AUTOSAR XML (schema 4-2-1)
package /VehicleProject
  system System
package /NM
  nm config NmConfig: can-nm-cluster-coupling=coupled-cluster=CAN00_CAN
    can nm cluster CAN00_CAN: communication-cluster=CAN00, nm-channel-id=0, nm-msg-cycle-time=0.1, nm-network-timeout=1, nm-repeat-message-time=0.4, nm-user-data-length=6, nm-wait-bus-sleep-time=0.75
      can nm node MyECU: controller=CT_CAN00, nm-if-ecu=MyECU_CAN, nm-node-id=0, rx-nm-pdu=msg_nm_RearECU_oCAN00, tx-nm-pdu=msg_nm_MyECU_oCAN00, nm-msg-cycle-offset=0, nm-msg-reduced-time=0.05, nm-range-config={lower-can-id=1024, upper-can-id=1087}
      can nm node RearECU: nm-if-ecu=RearECU_CAN, nm-node-id=1, rx-nm-pdu=msg_nm_MyECU_oCAN00, tx-nm-pdu=msg_nm_RearECU_oCAN00, nm-msg-cycle-offset=0, nm-msg-reduced-time=0.05, nm-range-config={lower-can-id=1024, upper-can-id=1087}
      can nm node Tester: nm-if-ecu=Tester_CAN, nm-node-id=0, nm-passive-mode-enabled=true, nm-msg-cycle-offset=0, nm-msg-reduced-time=0.05, nm-range-config={lower-can-id=1024, upper-can-id=1087}
    nm-if-ecus:
      nm ecu MyECU_CAN: ecu-instance=MyECU, nm-node-id-enabled=true, nm-user-data-enabled=true
      nm ecu RearECU_CAN: nm-node-id-enabled=true, nm-user-data-enabled=true
      nm ecu Tester_CAN: nm-node-id-enabled=true, nm-passive-mode-enabled=true, nm-user-data-enabled=true
package /TP
  can tp config CAN00_CAN: communication-cluster=CAN00, can-tp-ecu{cycle-time-main-function=0.005, ecu-instance=MyECU}
    can tp channel TPCH: channel-id=0, channel-mode=FULL-DUPLEX-MODE
    can-tp-connection addressing-format=STANDARD, can-tp-channel=TPCH, data-pdu=msg_diag_RequestGlobal_Tp_oCAN00, receiver=TN_MyECU, ta-type=FUNCTIONAL, tp-sdu=msg_diag_RequestGlobal_oCAN00, transmitter=TN_Tester:
      ident msg_diag_RequestGlobal_oTN_Tester
    can-tp-connection addressing-format=STANDARD, can-tp-channel=TPCH, data-pdu=msg_diag_Request_MyECU_Tp_oCAN00, flow-control-pdu=msg_diag_Response_MyECU_Tp_oCAN00, receiver=TN_MyECU, ta-type=PHYSICAL, tp-sdu=msg_diag_Request_MyECU_oCAN00, transmitter=TN_Tester:
      ident msg_diag_Request_MyECU_oTN_MyECU
    can-tp-connection addressing-format=STANDARD, can-tp-channel=TPCH, data-pdu=msg_diag_Response_MyECU_Tp_oCAN00, flow-control-pdu=msg_diag_Request_MyECU_Tp_oCAN00, receiver=TN_Tester, ta-type=PHYSICAL, tp-sdu=msg_diag_Response_MyECU_oCAN00, transmitter=TN_MyECU:
      ident msg_diag_Response_MyECU_oTN_MyECU
    can tp node TN_MyECU: connector=CN_CAN00
    can tp node TN_Tester
package /Cluster
  can cluster CAN00: protocol-name=CAN
    can physical channel CHNL: comm-connectors=CN_CAN00
      frame msg_diag_Request_MyECU_oCAN00: id 0x610, to MyECU, frame-length=8, can-addressing-mode=STANDARD
        n pdu msg_diag_Request_MyECU_Tp_oCAN00: length=8
      frame msg_diag_RequestGlobal_oCAN00: id 0x614, to MyECU, frame-length=8, can-addressing-mode=STANDARD
        n pdu msg_diag_RequestGlobal_Tp_oCAN00: length=8
      frame msg_diag_Response_MyECU_oCAN00: id 0x612, from MyECU, frame-length=8, can-addressing-mode=STANDARD
        n pdu msg_diag_Response_MyECU_Tp_oCAN00: length=8
      frame msg_MyECU_Lamp_oCAN00: id 0x511, from MyECU, frame-length=8, can-addressing-mode=STANDARD
        pdu msg_MyECU_Lamp_oCAN00: length=8, minimum-delay=0, transmission-mode-false-timing=cyclic-timing={time-offset=0, time-period=0.1}, transmission-mode-true-timing=cyclic-timing={time-offset=0, time-period=0.1}, unused-bit-pattern=0
          signal sig_LampCnt_omsg_MyECU_Lamp_oCAN00: start 7, 8 bit, big-endian, init-value=0, base-type=uint8, data-constr=DC_sig_LampCnt, transfer-property=PENDING
      frame msg_nm_MyECU_oCAN00: id 0x400, from MyECU, frame-length=8, can-addressing-mode=STANDARD
        nm pdu msg_nm_MyECU_oCAN00: length=8, unused-bit-pattern=0
      frame msg_nm_RearECU_oCAN00: id 0x401, to MyECU, frame-length=8, can-addressing-mode=STANDARD
        nm pdu msg_nm_RearECU_oCAN00: length=8, unused-bit-pattern=0
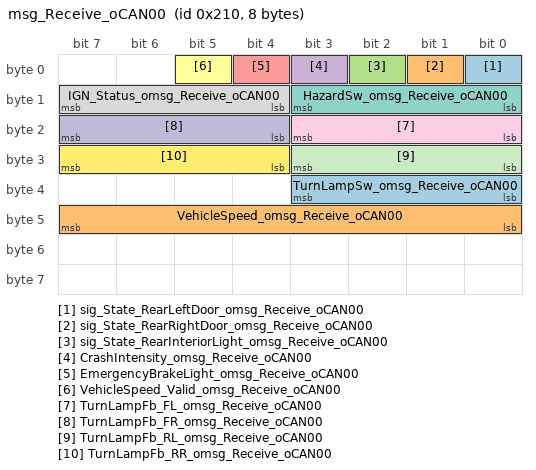
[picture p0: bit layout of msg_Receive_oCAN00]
      frame msg_Receive_oCAN00: id 0x210, to MyECU, frame-length=8, can-addressing-mode=STANDARD
        pdu msg_Receive_oCAN00: length=8, minimum-delay=0, transmission-mode-false-timing=cyclic-timing={time-offset=0, time-period=0.1}, transmission-mode-true-timing=cyclic-timing={time-offset=0, time-period=0.1}, unused-bit-pattern=0
          signal sig_State_RearLeftDoor_omsg_Receive_oCAN00: start 0, 1 bit, little-endian, init-value=0, base-type=boolean, data-constr=DC_sig_State_RearLeftDoor, transfer-property=PENDING, to MyECU
          signal sig_State_RearRightDoor_omsg_Receive_oCAN00: start 1, 1 bit, little-endian, init-value=0, base-type=boolean, data-constr=DC_sig_State_RearRightDoor, transfer-property=PENDING, to MyECU
          signal sig_State_RearInteriorLight_omsg_Receive_oCAN00: start 2, 1 bit, little-endian, init-value=0, base-type=boolean, data-constr=DC_sig_State_RearInteriorLight, transfer-property=PENDING, to MyECU
          signal CrashIntensity_omsg_Receive_oCAN00: start 3, 1 bit, little-endian, init-value=0, base-type=boolean, compu-method=CM_CrashIntensity, data-constr=DC_CrashIntensity, transfer-property=PENDING, to MyECU
          signal EmergencyBrakeLight_omsg_Receive_oCAN00: start 4, 1 bit, little-endian, init-value=0, base-type=boolean, compu-method=CM_EmergencyBrakeLight, transfer-property=PENDING, to MyECU
          signal VehicleSpeed_Valid_omsg_Receive_oCAN00: start 5, 1 bit, little-endian, init-value=0, base-type=boolean, compu-method=CM_VehicleSpeed_Valid, transfer-property=PENDING, to MyECU
          signal HazardSw_omsg_Receive_oCAN00: start 8, 4 bit, little-endian, init-value=0, base-type=uint8, compu-method=CM_HazardSw, data-constr=DC_HazardSw, transfer-property=PENDING, to MyECU
          signal IGN_Status_omsg_Receive_oCAN00: start 12, 4 bit, little-endian, init-value=0, base-type=uint8, compu-method=CM_IGN_Status, data-constr=DC_IGN_Status, transfer-property=PENDING, to MyECU
          signal TurnLampFb_FL_omsg_Receive_oCAN00: start 16, 4 bit, little-endian, init-value=0, base-type=uint8, compu-method=CM_TurnLampFb_FL, data-constr=DC_TurnLampFb_FL, transfer-property=PENDING, to MyECU
          signal TurnLampFb_FR_omsg_Receive_oCAN00: start 20, 4 bit, little-endian, init-value=0, base-type=uint8, compu-method=CM_TurnLampFb_FR, data-constr=DC_TurnLampFb_FR, transfer-property=PENDING, to MyECU
          signal TurnLampFb_RL_omsg_Receive_oCAN00: start 24, 4 bit, little-endian, init-value=0, base-type=uint8, compu-method=CM_TurnLampFb_RL, data-constr=DC_TurnLampFb_RL, transfer-property=PENDING, to MyECU
          signal TurnLampFb_RR_omsg_Receive_oCAN00: start 28, 4 bit, little-endian, init-value=0, base-type=uint8, compu-method=CM_TurnLampFb_RR, data-constr=DC_TurnLampFb_RR, transfer-property=PENDING, to MyECU
          signal TurnLampSw_omsg_Receive_oCAN00: start 32, 4 bit, little-endian, init-value=0, base-type=uint8, compu-method=CM_TurnLampSw, data-constr=DC_TurnLampSw, transfer-property=PENDING, to MyECU
          signal VehicleSpeed_omsg_Receive_oCAN00: start 40, 8 bit, little-endian, init-value=0, base-type=uint8, compu-method=CM_VehicleSpeed, transfer-property=PENDING, to MyECU
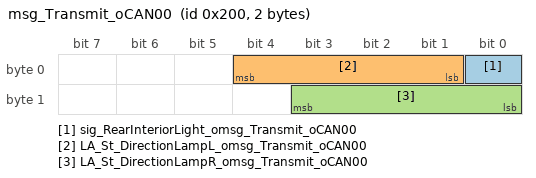
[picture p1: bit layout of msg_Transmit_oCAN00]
      frame msg_Transmit_oCAN00: id 0x200, from MyECU, frame-length=2, can-addressing-mode=STANDARD
        pdu msg_Transmit_oCAN00: length=2, minimum-delay=0, transmission-mode-false-timing=cyclic-timing={time-offset=0, time-period=0.1}, transmission-mode-true-timing=cyclic-timing={time-offset=0, time-period=0.1}, unused-bit-pattern=0
          signal sig_RearInteriorLight_omsg_Transmit_oCAN00: start 0, 1 bit, little-endian, init-value=0, base-type=boolean, data-constr=DC_sig_RearInteriorLight, transfer-property=PENDING
          signal LA_St_DirectionLampL_omsg_Transmit_oCAN00: start 1, 4 bit, little-endian, init-value=0, base-type=uint8, compu-method=CM_LA_St_DirectionLampL, data-constr=DC_LA_St_DirectionLampL, transfer-property=PENDING
          signal LA_St_DirectionLampR_omsg_Transmit_oCAN00: start 8, 4 bit, little-endian, init-value=0, base-type=uint8, compu-method=CM_LA_St_DirectionLampR, data-constr=DC_LA_St_DirectionLampR, transfer-property=PENDING
      pdu triggering PT_msg_diag_Request_MyECU: pdu=msg_diag_Request_MyECU_oCAN00, to MyECU
      pdu triggering PT_msg_diag_RequestGlobal: pdu=msg_diag_RequestGlobal_oCAN00, to MyECU
      pdu triggering PT_msg_diag_Response_MyECU: pdu=msg_diag_Response_MyECU_oCAN00, from MyECU
package /ECU
  ecu instance MyECU: associated-com-i-pdu-group=[MyECU_oCAN00_Rx, MyECU_oCAN00_Tx]
    can communication controller CT_CAN00
    can communication connector CN_CAN00: comm-controller=CT_CAN00
package /IPDUGroup
  i signal i pdu group MyECU_oCAN00_Rx: communication-direction=IN, i-signal-i-pdus=msg_Receive_oCAN00
  i signal i pdu group MyECU_oCAN00_Tx: communication-direction=OUT, i-signal-i-pdus=[msg_MyECU_Lamp_oCAN00, msg_Transmit_oCAN00]
package /PDU
  dcm i pdu msg_diag_Request_MyECU_oCAN00: length=8, diag-pdu-type=DIAG-REQUEST
  dcm i pdu msg_diag_RequestGlobal_oCAN00: length=7, diag-pdu-type=DIAG-REQUEST
  dcm i pdu msg_diag_Response_MyECU_oCAN00: length=8, diag-pdu-type=DIAG-RESPONSE
